# STM32WBA52 register map
File version: 0.1
CPU: CM33 r0p1, little endian, MPU, FPU, 4 interrupt priority bits
Registers are 32-bit, read-write, reset 0x0 unless marked. A register's access mark holds for its fields unless they carry their own. Offsets are from the block's base; [hi:lo] are bit positions; {n}, {i} and the like mark numbered series.

## TIM1 (part 2 of 2) — Advanced-control timers
Base 0x40012C00
Same registers: SEC_TIM1 0x50012C00
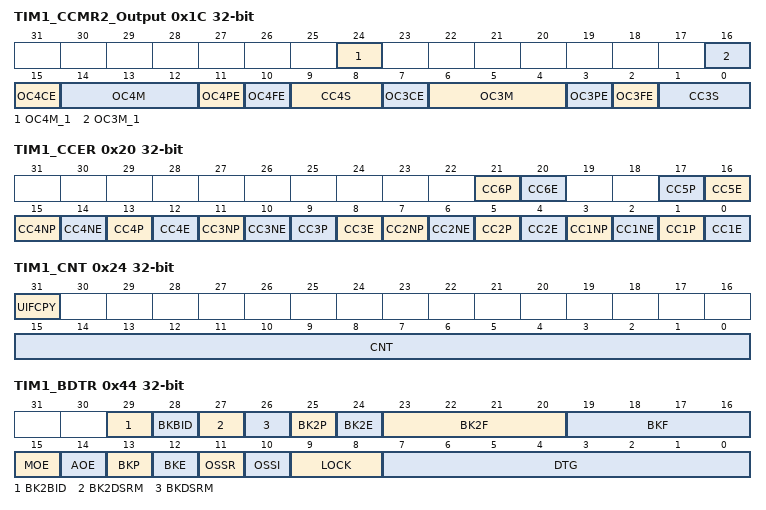
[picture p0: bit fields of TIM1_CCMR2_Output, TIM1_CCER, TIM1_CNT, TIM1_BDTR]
0x1C TIM1_CCMR2_Output (alternate view of TIM1_CCMR2_Input) — TIM1 capture/compare mode register 2 [alternate]
  [24] OC4M_1 — OC4M[3]
  [16] OC3M_1 — OC3M[3]
  [15] OC4CE — Output compare 4 clear enable
  [14:12] OC4M — OC4M[2:0]: Output compare 4 mode Refer to OC3M[3:0] bit description
  [11] OC4PE — Output compare 4 preload enable
  [10] OC4FE — Output compare 4 fast enable
  [9:8] CC4S — Capture/compare 4 selection This bit-field defines the direction of the channel (input/output) as well as the used input. Note: CC4S bits are writable only when the channel is OFF (CC4E = ‘0’ in TIMx_CCER).
    0=CC4 channel is configured as output; 1=CC4 channel is configured as input, tim_ic4 is mapped on tim_ti4; 2=CC4 channel is configured as input, tim_ic4 is mapped on tim_ti3; 3=CC4 channel is configured as input, tim_ic4 is mapped on tim_trc. This mode is working only if an internal trigger input is selected through TS bit (TIMx_SMCR register)
  [7] OC3CE — Output compare 3 clear enable
  [6:4] OC3M — OC3M[2:0]: Output compare 3 mode These bits define the behavior of the output reference signal tim_oc3ref from which tim_oc3 and tim_oc3n are derived. tim_oc3ref is active high whereas tim_oc3 and tim_oc3n active level depends on CC3P and CC3NP bits. Note: These bits can not be modified as long as LOCK level 3 has been programmed (LOCK bits in TIMx_BDTR register) and CC1S=’00’ (the channel is configured in output). Note: In PWM mode, the OCREF level changes only when the result of the comparison changes or when the output compare mode switches from “frozen” mode to “PWM” mode. On channels having a complementary output, this bit field is preloaded. If the CCPC bit is set in the TIMx_CR2 register then the OC3M active bits take the new value from the preloaded bits only when a COM event is generated.
    0=Frozen - The comparison between the output compare register TIMx_CCR3 and the counter TIMx_CNT has no effect on the outputs.(this mode is used to generate a timing base); 1=Set channel 3 to active level on match. tim_oc3ref signal is forced high when the counter TIMx_CNT matches the capture/compare register 3 (TIMx_CCR3).; 2=Set channel 3 to inactive level on match. tim_oc3ref signal is forced low when the counter TIMx_CNT matches the capture/compare register 3 (TIMx_CCR3).; 3=Toggle - tim_oc3ref toggles when TIMx_CNT=TIMx_CCR3; 4=Force inactive level - tim_oc3ref is forced low; 5=Force active level - tim_oc3ref is forced high; 6=PWM mode 1 - In upcounting, channel 3 is active as long as TIMx_CNT<TIMx_CCR3 else inactive. In downcounting, channel 3 is inactive (tim_oc3ref=‘0’) as long as TIMx_CNT>TIMx_CCR3 else active (tim_oc3ref=’1’).; 7=PWM mode 2 - In upcounting, channel 3 is inactive as long as TIMx_CNT<TIMx_CCR3 else active. In downcounting, channel 3 is active as long as TIMx_CNT>TIMx_CCR3 else inactive.; 8=Retrigerrable OPM mode 1 - In up-counting mode, the channel is active until a trigger event is detected (on tim_trgi signal). Then, a comparison is performed as in PWM mode 1 and the channels becomes active again at the next update. In down-counting mode, the channel is inactive until a trigger event is detected (on tim_trgi signal). Then, a comparison is performed as in PWM mode 1 and the channels becomes inactive again at the next update.; 9=Retrigerrable OPM mode 2 - In up-counting mode, the channel is inactive until a trigger event is detected (on tim_trgi signal). Then, a comparison is performed as in PWM mode 2 and the channels becomes inactive again at the next update. In down-counting mode, the channel is active until a trigger event is detected (on tim_trgi signal). Then, a comparison is performed as in PWM mode 1 and the channels becomes active again at the next update.; 10=Pulse on compare: a pulse is generated on tim_oc3ref upon CCR3 match event, as per PWPRSC[2:0] and PW[7:0] bitfields programming in TIMxECR; 11=Direction output. The tim_oc3ref signal is overridden by a copy of the DIR bit.; 12=Combined PWM mode 1 - tim_oc3ref has the same behavior as in PWM mode 1. tim_oc3refc is the logical OR between tim_oc3ref and tim_oc4ref.; 13=Combined PWM mode 2 - tim_oc3ref has the same behavior as in PWM mode 2. tim_oc3refc is the logical AND between tim_oc3ref and tim_oc4ref.; 14=Asymmetric PWM mode 1 - tim_oc3ref has the same behavior as in PWM mode 1. tim_oc3refc outputs tim_oc3ref when the counter is counting up, tim_oc4ref when it is counting down.; 15=Asymmetric PWM mode 2 - tim_oc3ref has the same behavior as in PWM mode 2. tim_oc3refc outputs tim_oc3ref when the counter is counting up, tim_oc4ref when it is counting down.
  [3] OC3PE — Output compare 3 preload enable
  [2] OC3FE — Output compare 3 fast enable
  [1:0] CC3S — Capture/compare 3 selection This bit-field defines the direction of the channel (input/output) as well as the used input. Note: CC3S bits are writable only when the channel is OFF (CC3E = ‘0’ in TIMx_CCER).
    0=CC3 channel is configured as output; 1=CC3 channel is configured as input, tim_ic3 is mapped on tim_ti3; 2=CC3 channel is configured as input, tim_ic3 is mapped on tim_ti4; 3=CC3 channel is configured as input, tim_ic3 is mapped on tim_trc. This mode is working only if an internal trigger input is selected through TS bit (TIMx_SMCR register)
0x20 TIM1_CCER — TIM1 capture/compare enable register
  [4n-3] CC{n}P (n=2..6) — Capture/compare {n} output polarity Refer to CC1P description
  [4n-4] CC{n}E (n=2..6) — Capture/compare {n} output enable Refer to CC1E description
  [15] CC4NP — Capture/compare 4 complementary output polarity Refer to CC1NP description
  [14] CC4NE — Capture/compare 4 complementary output enable Refer to CC1NE description
  [11] CC3NP — Capture/compare 3 complementary output polarity Refer to CC1NP description
  [10] CC3NE — Capture/compare 3 complementary output enable Refer to CC1NE description
  [7] CC2NP — Capture/compare 2 complementary output polarity Refer to CC1NP description
  [6] CC2NE — Capture/compare 2 complementary output enable Refer to CC1NE description
  [3] CC1NP — Capture/compare 1 complementary output polarity CC1 channel configured as output: CC1 channel configured as input: This bit is used in conjunction with CC1P to define the polarity of tim_ti1fp1 and tim_ti2fp1. Refer to CC1P description. Note: This bit is not writable as soon as LOCK level 2 or 3 has been programmed (LOCK bits in TIMx_BDTR register) and CC1S=”00” (channel configured as output). Note: On channels having a complementary output, this bit is preloaded. If the CCPC bit is set in the TIMx_CR2 register then the CC1NP active bit takes the new value from the preloaded bit only when a Commutation event is generated.
    0=tim_oc1n active high; 1=tim_oc1n active low
  [2] CC1NE — Capture/compare 1 complementary output enable Note: On channels having a complementary output, this bit is preloaded. If the CCPC bit is set in the TIMx_CR2 register then the CC1NE active bit takes the new value from the preloaded bit only when a Commutation event is generated.
    0=Off - tim_oc1n is not active. tim_oc1n level is then function of MOE, OSSI, OSSR, OIS1, OIS1N and CC1E bits.; 1=On - tim_oc1n signal is output on the corresponding output pin depending on MOE, OSSI, OSSR, OIS1, OIS1N and CC1E bits
  [1] CC1P — Capture/compare 1 output polarity When CC1 channel is configured as input, both CC1NP/CC1P bits select the active polarity of TI1FP1 and TI2FP1 for trigger or capture operations. CC1NP=0, CC1P=0: non-inverted/rising edge. The circuit is sensitive to TIxFP1 rising edge (capture or trigger operations in reset, external clock or trigger mode), TIxFP1 is not inverted (trigger operation in gated mode or encoder mode). CC1NP=0, CC1P=1: inverted/falling edge. The circuit is sensitive to TIxFP1 falling edge (capture or trigger operations in reset, external clock or trigger mode), TIxFP1 is inverted (trigger operation in gated mode or encoder mode). CC1NP=1, CC1P=1: non-inverted/both edges/ The circuit is sensitive to both TIxFP1 rising and falling edges (capture or trigger operations in reset, external clock or trigger mode), TIxFP1is not inverted (trigger operation in gated mode). This configuration must not be used in encoder mode. CC1NP=1, CC1P=0: the configuration is reserved, it must not be used. Note: This bit is not writable as soon as LOCK level 2 or 3 has been programmed (LOCK bits in TIMx_BDTR register). Note: On channels having a complementary output, this bit is preloaded. If the CCPC bit is set in the TIMx_CR2 register then the CC1P active bit takes the new value from the preloaded bit only when a Commutation event is generated.
    0=OC1 active high (output mode) / Edge sensitivity selection (input mode, see below); 1=OC1 active low (output mode) / Edge sensitivity selection (input mode, see below)
  [0] CC1E — Capture/compare 1 output enable When CC1 channel is configured as output, the OC1 level depends on MOE, OSSI, OSSR, OIS1, OIS1N and CC1NE bits, regardless of the CC1E bits state. Refer to Table�272 for details. Note: On channels having a complementary output, this bit is preloaded. If the CCPC bit is set in the TIMx_CR2 register then the CC1E active bit takes the new value from the preloaded bit only when a Commutation event is generated.
    0=Capture mode disabled / OC1 is not active (see below); 1=Capture mode enabled / OC1 signal is output on the corresponding output pin
0x24 TIM1_CNT access per field — TIM1 counter
  [31] UIFCPY ro — UIF copy This bit is a read-only copy of the UIF bit of the TIMx_ISR register. If the UIFREMAP bit in the TIMxCR1 is reset, bit 31 is reserved and read at 0.
  [15:0] CNT rw — Counter value Non-dithering mode (DITHEN = 0) The register holds the counter value. Dithering mode (DITHEN = 1) The register only holds the non-dithered part in CNT[15:0]. The fractional part is not available.
0x28 TIM1_PSC 16-bit — TIM1 prescaler
  [15:0] PSC — Prescaler value The counter clock frequency (f<sub>tim_cnt_ck</sub>) is equal to f<sub>tim_psc_ck</sub> / (PSC[15:0] + 1). PSC contains the value to be loaded in the active prescaler register at each update event (including when the counter is cleared through UG bit of TIMx_EGR register or through trigger controller when configured in “reset mode”).
0x2C TIM1_ARR reset 0xFFFF — TIM1 auto-reload register
  [19:0] ARR — Auto-reload value ARR is the value to be loaded in the actual auto-reload register. Refer to the Section�28.3.3: Time-base unit on page�1112 for more details about ARR update and behavior. The counter is blocked while the auto-reload value is null. Non-dithering mode (DITHEN = 0) The register holds the auto-reload value. Dithering mode (DITHEN = 1) The register holds the integer part in ARR[19:4]. The ARR[3:0] bitfield contains the dithered part.
0x30 TIM1_RCR 16-bit — TIM1 repetition counter register
  [15:0] REP — Repetition counter reload value This bitfield defines the update rate of the compare registers (i.e. periodic transfers from preload to active registers) when preload registers are enable. It also defines the update interrupt generation rate, if this interrupt is enable. When the repetition down-counter reaches zero, an update event is generated and it restarts counting from REP value. As the repetition counter is reloaded with REP value only at the repetition update event UEV, any write to the TIMx_RCR register is not taken in account until the next repetition update event. It means in PWM mode (REP+1) corresponds to: the number of PWM periods in edge-aligned mode the number of half PWM period in center-aligned mode.
0x34 TIM1_CCR1 — TIM1 capture/compare register 1
  [19:0] CCR1 — Capture/compare 1 value If channel CC1 is configured as output: CCR1 is the value to be loaded in the actual capture/compare 1 register (preload value). It is loaded permanently if the preload feature is not selected in the TIMx_CCMR1 register (bit OC1PE). Else the preload value is copied in the active capture/compare 1 register when an update event occurs. The active capture/compare register contains the value to be compared to the counter TIMx_CNT and signaled on tim_oc1 output. Non-dithering mode (DITHEN = 0) The register holds the compare value in CCR1[15:0]. The CCR1[19:16] bits are reset. Dithering mode (DITHEN = 1) The register holds the integer part in CCR1[19:4]. The CCR1[3:0] bitfield contains the dithered part. If channel CC1 is configured as input: CR1 is the counter value transferred by the last input capture 1 event (tim_ic1). The TIMx_CCR1 register is read-only and cannot be programmed. Non-dithering mode (DITHEN = 0) The register holds the capture value in CCR1[15:0]. The CCR1[19:16] bits are reset. Dithering mode (DITHEN = 1) The register holds the capture in CCR1[19:4]. The CCR1[3:0] bits are reset.
0x38 TIM1_CCR2 — TIM1 capture/compare register 2
  [19:0] CCR2 — Capture/compare 2 value If channel CC2 is configured as output: CCR2 is the value to be loaded in the actual capture/compare 2 register (preload value). It is loaded permanently if the preload feature is not selected in the TIMx_CCMR1 register (bit OC2PE). Else the preload value is copied in the active capture/compare 2 register when an update event occurs. The active capture/compare register contains the value to be compared to the counter TIMx_CNT and signaled on tim_oc2 output. Non-dithering mode (DITHEN = 0) The register holds the compare value in CCR2[15:0]. The CCR2[19:16] bits are reset. Dithering mode (DITHEN = 1) The register holds the integer part in CCR2[19:4]. The CCR2[3:0] bitfield contains the dithered part. If channel CC2 is configured as input: CCR2 is the counter value transferred by the last input capture 2 event (tim_ic2). The TIMx_CCR2 register is read-only and cannot be programmed. Non-dithering mode (DITHEN = 0) The register holds the capture value in CCR2[15:0]. The CCR2[19:16] bits are reset. Dithering mode (DITHEN = 1) The register holds the capture in CCR2[19:4]. The CCR2[3:0] bits are reset.
0x3C TIM1_CCR3 — TIM1 capture/compare register 3
  [19:0] CCR3 — Capture/compare value If channel CC3 is configured as output: CCR3 is the value to be loaded in the actual capture/compare 3 register (preload value). It is loaded permanently if the preload feature is not selected in the TIMx_CCMR2 register (bit OC3PE). Else the preload value is copied in the active capture/compare 3 register when an update event occurs. The active capture/compare register contains the value to be compared to the counter TIMx_CNT and signaled on tim_oc3 output. Non-dithering mode (DITHEN = 0) The register holds the compare value in CCR3[15:0]. The CCR3[19:16] bits are reset. Dithering mode (DITHEN = 1) The register holds the integer part in CCR3[19:4]. The CCR3[3:0] bitfield contains the dithered part. If channel CC3 is configured as input: CCR3 is the counter value transferred by the last input capture 3 event (tim_ic3). The TIMx_CCR3 register is read-only and cannot be programmed. Non-dithering mode (DITHEN = 0) The register holds the capture value in CCR3[15:0]. The CCR3[19:16] bits are reset. Dithering mode (DITHEN = 1) The register holds the capture in CCR3[19:4]. The CCR3[3:0] bits are reset.
0x40 TIM1_CCR4 — TIM1 capture/compare register 4
  [19:0] CCR4 — Capture/compare value If channel CC4 is configured as output: CCR4 is the value to be loaded in the actual capture/compare 4 register (preload value). It is loaded permanently if the preload feature is not selected in the TIMx_CCMR2 register (bit OC4PE). Else the preload value is copied in the active capture/compare 4 register when an update event occurs. The active capture/compare register contains the value to be compared to the counter TIMx_CNT and signalled on tim_oc4 output. Non-dithering mode (DITHEN = 0) The register holds the compare value in CCR4[15:0]. The CCR4[19:16] bits are reset. Dithering mode (DITHEN = 1) The register holds the integer part in CCR4[19:4]. The CCR4[3:0] bitfield contains the dithered part. If channel CC4 is configured as input: CCR4 is the counter value transferred by the last input capture 4 event (tim_ic4). The TIMx_CCR4 register is read-only and cannot be programmed. Non-dithering mode (DITHEN = 0) The register holds the capture value in CCR4[15:0]. The CCR4[19:16] bits are reset. Dithering mode (DITHEN = 1) The register holds the capture in CCR4[19:4]. The CCR4[3:0] bits are reset.
0x44 TIM1_BDTR — TIM1 break and dead-time register
  [29] BK2BID — Break2 bidirectional Refer to BKBID description
  [28] BKBID — Break bidirectional In the bidirectional mode (BKBID bit set to 1), the break input is configured both in input mode and in open drain output mode. Any active break event asserts a low logic level on the Break input to indicate an internal break event to external devices. Note: This bit cannot be modified as long as LOCK level 1 has been programmed (LOCK bits in TIMx_BDTR register). Note: Any write operation to this bit takes a delay of 1 APB clock cycle to become effective.
    0=Break input tim_brk in input mode; 1=Break input tim_brk in bidirectional mode
  [27] BK2DSRM — Break2 disarm Refer to BKDSRM description
  [26] BKDSRM — Break disarm This bit is cleared by hardware when no break source is active. The BKDSRM bit must be set by software to release the bidirectional output control (open-drain output in Hi-Z state) and then be polled it until it is reset by hardware, indicating that the fault condition has disappeared. Note: Any write operation to this bit takes a delay of 1 APB clock cycle to become effective.
    0=Break input tim_brk is armed; 1=Break input tim_brk is disarmed
  [25] BK2P — Break 2 polarity Note: This bit cannot be modified as long as LOCK level 1 has been programmed (LOCK bits in TIMx_BDTR register). Note: Any write operation to this bit takes a delay of 1 APB clock cycle to become effective.
    0=Break input tim_brk2 is active low; 1=Break input tim_brk2 is active high
  [24] BK2E — Break 2 enable This bit enables the complete break 2 protection (including all sources connected to bk_acth and BKIN sources, as per Figure�316: Break and Break2 circuitry overview). Note: The BRKIN2 must only be used with OSSR = OSSI = 1. Note: This bit cannot be modified when LOCK level 1 has been programmed (LOCK bits in TIMx_BDTR register). Note: Any write operation to this bit takes a delay of 1 APB clock cycle to become effective.
    0=Break2 function disabled; 1=Break2 function enabled
  [23:20] BK2F — Break 2 filter This bit-field defines the frequency used to sample tim_brk2 input and the length of the digital filter applied to tim_brk2. The digital filter is made of an event counter in which N consecutive events are needed to validate a transition on the output: Note: This bit cannot be modified when LOCK level 1 has been programmed (LOCK bits in TIMx_BDTR register).
    0=No filter, tim_brk2 acts asynchronously; 1=f<sub>SAMPLING</sub>=f<sub>tim_ker_ck</sub>, N=2; 2=f<sub>SAMPLING</sub>=f<sub>tim_ker_ck</sub>, N=4; 3=f<sub>SAMPLING</sub>=f<sub>tim_ker_ck</sub>, N=8; 4=f<sub>SAMPLING</sub>=f<sub>DTS</sub>/2, N=6; 5=f<sub>SAMPLING</sub>=f<sub>DTS</sub>/2, N=8; 6=f<sub>SAMPLING</sub>=f<sub>DTS</sub>/4, N=6; 7=f<sub>SAMPLING</sub>=f<sub>DTS</sub>/4, N=8; 8=f<sub>SAMPLING</sub>=f<sub>DTS</sub>/8, N=6; 9=f<sub>SAMPLING</sub>=f<sub>DTS</sub>/8, N=8; 10=f<sub>SAMPLING</sub>=f<sub>DTS</sub>/16, N=5; 11=f<sub>SAMPLING</sub>=f<sub>DTS</sub>/16, N=6; 12=f<sub>SAMPLING</sub>=f<sub>DTS</sub>/16, N=8; 13=f<sub>SAMPLING</sub>=f<sub>DTS</sub>/32, N=5; 14=f<sub>SAMPLING</sub>=f<sub>DTS</sub>/32, N=6; 15=f<sub>SAMPLING</sub>=f<sub>DTS</sub>/32, N=8
  [19:16] BKF — Break filter This bit-field defines the frequency used to sample tim_brk input and the length of the digital filter applied to tim_brk. The digital filter is made of an event counter in which N consecutive events are needed to validate a transition on the output: Note: This bit cannot be modified when LOCK level 1 has been programmed (LOCK bits in TIMx_BDTR register).
    0=No filter, tim_brk acts asynchronously; 1=f<sub>SAMPLING</sub>=f<sub>tim_ker_ck</sub>, N=2; 2=f<sub>SAMPLING</sub>=f<sub>tim_ker_ck</sub>, N=4; 3=f<sub>SAMPLING</sub>=f<sub>tim_ker_ck</sub>, N=8; 4=f<sub>SAMPLING</sub>=f<sub>DTS</sub>/2, N=6; 5=f<sub>SAMPLING</sub>=f<sub>DTS</sub>/2, N=8; 6=f<sub>SAMPLING</sub>=f<sub>DTS</sub>/4, N=6; 7=f<sub>SAMPLING</sub>=f<sub>DTS</sub>/4, N=8; 8=f<sub>SAMPLING</sub>=f<sub>DTS</sub>/8, N=6; 9=f<sub>SAMPLING</sub>=f<sub>DTS</sub>/8, N=8; 10=f<sub>SAMPLING</sub>=f<sub>DTS</sub>/16, N=5; 11=f<sub>SAMPLING</sub>=f<sub>DTS</sub>/16, N=6; 12=f<sub>SAMPLING</sub>=f<sub>DTS</sub>/16, N=8; 13=f<sub>SAMPLING</sub>=f<sub>DTS</sub>/32, N=5; 14=f<sub>SAMPLING</sub>=f<sub>DTS</sub>/32, N=6; 15=f<sub>SAMPLING</sub>=f<sub>DTS</sub>/32, N=8
  [15] MOE — Main output enable This bit is cleared asynchronously by hardware as soon as one of the break inputs is active (tim_brk or tim_brk2). It is set by software or automatically depending on the AOE bit. It is acting only on the channels which are configured in output. In response to a break event or if MOE is written to 0: OC and OCN outputs are disabled or forced to idle state depending on the OSSI bit. See OC/OCN enable description for more details (Section�28.6.11: TIM1 capture/compare enable register (TIM1_CCER)).
    0=In response to a break 2 event. OC and OCN outputs are disabled; 1=OC and OCN outputs are enabled if their respective enable bits are set (CCxE, CCxNE in TIMx_CCER register)
  [14] AOE — Automatic output enable Note: This bit can not be modified as long as LOCK level 1 has been programmed (LOCK bits in TIMx_BDTR register).
    0=MOE can be set only by software; 1=MOE can be set by software or automatically at the next update event (if none of the break inputs tim_brk and tim_brk2 is active)
  [13] BKP — Break polarity Note: This bit can not be modified as long as LOCK level 1 has been programmed (LOCK bits in TIMx_BDTR register). Note: Any write operation to this bit takes a delay of 1 APB clock cycle to become effective.
    0=Break input tim_brk is active low; 1=Break input tim_brk is active high
  [12] BKE — Break enable This bit enables the complete break protection (including all sources connected to bk_acth and BKIN sources, as per Figure�316: Break and Break2 circuitry overview). Note: This bit cannot be modified when LOCK level 1 has been programmed (LOCK bits in TIMx_BDTR register). Note: Any write operation to this bit takes a delay of 1 APB clock cycle to become effective.
    0=Break function disabled; 1=Break function enabled
  [11] OSSR — Off-state selection for Run mode This bit is used when MOE=1 on channels having a complementary output which are configured as outputs. OSSR is not implemented if no complementary output is implemented in the timer. See OC/OCN enable description for more details (Section�28.6.11: TIM1 capture/compare enable register (TIM1_CCER)). Note: This bit can not be modified as soon as the LOCK level 2 has been programmed (LOCK bits in TIMx_BDTR register).
    0=When inactive, OC/OCN outputs are disabled (the timer releases the output control which is taken over by the GPIO logic, which forces a Hi-Z state); 1=When inactive, OC/OCN outputs are enabled with their inactive level as soon as CCxE=1 or CCxNE=1 (the output is still controlled by the timer)
  [10] OSSI — Off-state selection for idle mode This bit is used when MOE=0 due to a break event or by a software write, on channels configured as outputs. See OC/OCN enable description for more details (Section�28.6.11: TIM1 capture/compare enable register (TIM1_CCER)). Note: This bit can not be modified as soon as the LOCK level 2 has been programmed (LOCK bits in TIMx_BDTR register).
    0=When inactive, OC/OCN outputs are disabled (the timer releases the output control which is taken over by the GPIO logic and which imposes a Hi-Z state); 1=When inactive, OC/OCN outputs are first forced with their inactive level then forced to their idle level after the deadtime. The timer maintains its control over the output.
  [9:8] LOCK — Lock configuration These bits offer a write protection against software errors. Note: The LOCK bits can be written only once after the reset. Once the TIMx_BDTR register has been written, their content is frozen until the next reset.
    0=LOCK OFF - No bit is write protected; 1=LOCK Level 1 = DTG bits in TIMx_BDTR register, OISx and OISxN bits in TIMx_CR2 register and BKBID/BK2BID/BKE/BKP/AOE bits in TIMx_BDTR register can no longer be written; 2=LOCK Level 2 = LOCK Level 1 + CC Polarity bits (CCxP/CCxNP bits in TIMx_CCER register, as long as the related channel is configured in output through the CCxS bits) as well as OSSR and OSSI bits can no longer be written; 3=LOCK Level 3 = LOCK Level 2 + CC Control bits (OCxM and OCxPE bits in TIMx_CCMRx registers, as long as the related channel is configured in output through the CCxS bits) can no longer be written
  [7:0] DTG — Dead-time generator setup This bit-field defines the duration of the dead-time inserted between the complementary outputs. DT correspond to this duration. DTG[7:5]=0xx => DT=DTG[7:0]x t<sub>dtg</sub> with t<sub>dtg</sub>=t<sub>DTS</sub>. DTG[7:5]=10x => DT=(64+DTG[5:0])xt<sub>dtg</sub> with T<sub>dtg</sub>=2xt<sub>DTS</sub>. DTG[7:5]=110 => DT=(32+DTG[4:0])xt<sub>dtg</sub> with T<sub>dtg</sub>=8xt<sub>DTS</sub>. DTG[7:5]=111 => DT=(32+DTG[4:0])xt<sub>dtg</sub> with T<sub>dtg</sub>=16xt<sub>DTS</sub>. Example if T<sub>DTS</sub>=125ns (8MHz), dead-time possible values are: 0 to 15875 ns by 125 ns steps, 16 us to 31750 ns by 250 ns steps, 32 us to 63us by 1 us steps, 64 us to 126 us by 2 us steps Note: This bit-field can not be modified as long as LOCK level 1, 2 or 3 has been programmed (LOCK bits in TIMx_BDTR register).
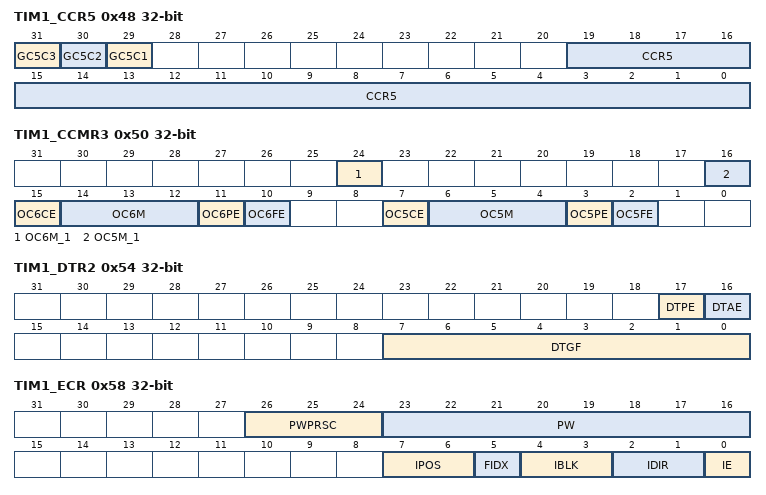
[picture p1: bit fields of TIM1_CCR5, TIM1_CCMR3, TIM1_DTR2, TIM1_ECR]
0x48 TIM1_CCR5 — TIM1 capture/compare register 5
  [31] GC5C3 — Group channel 5 and channel 3 Distortion on channel 3 output: This bit can either have immediate effect or be preloaded and taken into account after an update event (if preload feature is selected in TIMxCCMR2). Note: it is also possible to apply this distortion on combined PWM signals.
    0=No effect of tim_oc5ref on tim_oc3refc; 1=tim_oc3refc is the logical AND of tim_oc3ref and tim_oc5ref
  [30] GC5C2 — Group channel 5 and channel 2 Distortion on channel 2 output: This bit can either have immediate effect or be preloaded and taken into account after an update event (if preload feature is selected in TIMxCCMR1). Note: it is also possible to apply this distortion on combined PWM signals.
    0=No effect of tim_oc5ref on tim_oc2refc; 1=tim_oc2refc is the logical AND of tim_oc2ref and tim_oc5ref
  [29] GC5C1 — Group channel 5 and channel 1 Distortion on channel 1 output: This bit can either have immediate effect or be preloaded and taken into account after an update event (if preload feature is selected in TIMxCCMR1). Note: it is also possible to apply this distortion on combined PWM signals.
    0=No effect of oc5ref on oc1refc; 1=oc1refc is the logical AND of oc1ref and oc5ref
  [19:0] CCR5 — Capture/compare 5 value CCR5 is the value to be loaded in the actual capture/compare 5 register (preload value). It is loaded permanently if the preload feature is not selected in the TIMx_CCMR3 register (bit OC5PE). Else the preload value is copied in the active capture/compare 5 register when an update event occurs. The active capture/compare register contains the value to be compared to the counter TIMx_CNT and signaled on tim_oc5 output. Non-dithering mode (DITHEN = 0) The register holds the compare value in CCR5[15:0]. The CCR5[19:16] bits are reset. Dithering mode (DITHEN = 1) The register holds the integer part in CCR5[19:4]. The CCR5[3:0] bitfield contains the dithered part.
0x4C TIM1_CCR6 — TIM1 capture/compare register 6
  [19:0] CCR6 — Capture/compare 6 value CCR6 is the value to be loaded in the actual capture/compare 6 register (preload value). It is loaded permanently if the preload feature is not selected in the TIMx_CCMR3 register (bit OC6PE). Else the preload value is copied in the active capture/compare 6 register when an update event occurs. The active capture/compare register contains the value to be compared to the counter TIMx_CNT and signaled on tim_oc6 output. Non-dithering mode (DITHEN = 0) The register holds the compare value in CCR6[15:0]. The CCR6[19:16] bits are reset. Dithering mode (DITHEN = 1) The register holds the integer part in CCR6[19:4]. The CCR6[3:0] bitfield contains the dithered part.
0x50 TIM1_CCMR3 — TIM1 capture/compare mode register 3
  [24] OC6M_1 — OC6M[3]
  [16] OC5M_1 — OC5M[3]
  [15] OC6CE — Output compare 6 clear enable
  [14:12] OC6M — OC6M[2:0]: Output compare 6 mode
  [11] OC6PE — Output compare 6 preload enable
  [10] OC6FE — Output compare 6 fast enable
  [7] OC5CE — Output compare 5 clear enable
  [6:4] OC5M — OC5M[2:0]: Output compare 5 mode
  [3] OC5PE — Output compare 5 preload enable
  [2] OC5FE — Output compare 5 fast enable
0x54 TIM1_DTR2 — TIM1 timer deadtime register 2
  [17] DTPE — Deadtime preload enable Note: This bit can not be modified as long as LOCK level 1, 2 or 3 has been programmed (LOCK bits in TIMx_BDTR register).
    0=Deadtime value is not preloaded; 1=Deadtime value preload is enabled
  [16] DTAE — Deadtime asymmetric enable Note: This bit can not be modified as long as LOCK level 1, 2 or 3 has been programmed (LOCK bits in TIMx_BDTR register).
    0=Deadtime on rising and falling edges are identical, and defined with DTG[7:0] register; 1=Deadtime on rising edge is defined with DTG[7:0] register and deadtime on falling edge is defined with DTGF[7:0] bits
  [7:0] DTGF — Dead-time falling edge generator setup This bit-field defines the duration of the dead-time inserted between the complementary outputs, on the falling edge. DTGF[7:5]=0xx => DTF=DTGF[7:0]x t<sub>dtg</sub> with t<sub>dtg</sub>=t<sub>DTS</sub>. DTGF[7:5]=10x => DTF=(64+DTGF[5:0])xt<sub>dtg</sub> with T<sub>dtg</sub>=2xt<sub>DTS</sub>. DTGF[7:5]=110 => DTF=(32+DTGF[4:0])xt<sub>dtg</sub> with T<sub>dtg</sub>=8xt<sub>DTS</sub>. DTGF[7:5]=111 => DTF=(32+DTGF[4:0])xt<sub>dtg</sub> with T<sub>dtg</sub>=16xt<sub>DTS</sub>. Example if T<sub>DTS</sub>=125ns (8MHz), dead-time possible values are: 0 to 15875 ns by 125 ns steps, 16 us to 31750 ns by 250 ns steps, 32 us to 63us by 1 us steps, 64 us to 126 us by 2 us steps Note: This bit-field can not be modified as long as LOCK level 1, 2 or 3 has been programmed (LOCK bits in TIMx_BDTR register).
0x58 TIM1_ECR — TIM1 timer encoder control register
  [26:24] PWPRSC — Pulse width prescaler This bitfield sets the clock prescaler for the pulse generator, as following: t<sub>PWG</sub> = (2<sup>(PWPRSC[2:0])</sup>) x t<sub>tim_ker_ck</sub>
  [23:16] PW — Pulse width This bitfield defines the pulse duration, as following: t<sub>PW</sub> = PW[7:0] x t<sub>PWG</sub>
  [7:6] IPOS — Index positioning In quadrature encoder mode (SMS[3:0] = 0001, 0010, 0011, 1110, 1111), this bit indicates in which AB input configuration the Index event resets the counter. In directional clock mode or clock plus direction mode (SMS[3:0] = 1010, 1011, 1100, 1101), these bits indicates on which level the Index event resets the counter. In bidirectional clock mode, this applies for both clock inputs. x0: Index resets the counter when clock is 0 x1: Index resets the counter when clock is 1 Note: IPOS[1] bit is not significant
    0=Index resets the counter when AB = 00; 1=Index resets the counter when AB = 01; 2=Index resets the counter when AB = 10; 3=Index resets the counter when AB = 11
  [5] FIDX — First index This bit indicates if the first index only is taken into account
    0=Index is always active; 1=the first Index only resets the counter
  [4:3] IBLK — Index blanking This bit indicates if the Index event is conditioned by the tim_ti3 or tim_ti4 input
    0=Index always active; 1=Index disabled when tim_ti3 input is active, as per CC3P bitfield; 2=Index disabled when tim_ti4 input is active, as per CC4P bitfield
  [2:1] IDIR — Index direction This bit indicates in which direction the Index event resets the counter. Note: The IDR[1:0] bitfield must be written when IE bit is reset (index disabled).
    0=Index resets the counter whatever the direction; 1=Index resets the counter when up-counting only; 2=Index resets the counter when down-counting only
  [0] IE — Index enable This bit indicates if the Index event resets the counter.
    0=Index disabled; 1=Index enabled
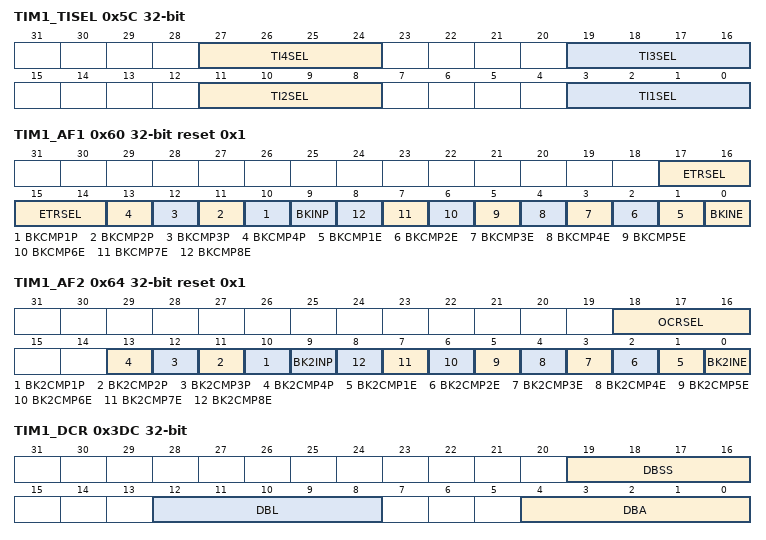
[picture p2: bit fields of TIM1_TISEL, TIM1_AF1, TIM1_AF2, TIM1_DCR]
0x5C TIM1_TISEL — TIM1 timer input selection register
  [27:24] TI4SEL — Selects tim_ti4[15:0] input ... Refer to Section�28.3.2: TIM1 pins and internal signals for interconnects list.
    0=tim_ti4_in0: TIMx_CH4; 1=tim_ti4_in1; 15=tim_ti4_in15
  [19:16] TI3SEL — Selects tim_ti3[15:0] input ... Refer to Section�28.3.2: TIM1 pins and internal signals for interconnects list.
    0=tim_ti3_in0: TIMx_CH2; 1=tim_ti3_in1; 15=tim_ti3_in15
  [11:8] TI2SEL — Selects tim_ti2[15:0] input ... Refer to Section�28.3.2: TIM1 pins and internal signals for interconnects list.
    0=tim_ti2_in0: TIMx_CH2; 1=tim_ti2_in1; 15=tim_ti2_in15
  [3:0] TI1SEL — Selects tim_ti1[15:0] input ... Refer to Section�28.3.2: TIM1 pins and internal signals for interconnects list.
    0=tim_ti1_in0: TIMx_CH1; 1=tim_ti1_in1; 15=tim_ti1_in15
0x60 TIM1_AF1 reset 0x1 — TIM1 alternate function option register 1
  [17:14] ETRSEL — etr_in source selection These bits select the etr_in input source. ... Refer to Section�28.3.2: TIM1 pins and internal signals for product specific implementation. Note: These bits can not be modified as long as LOCK level 1 has been programmed (LOCK bits in TIMx_BDTR register).
    0=tim_etr0: TIMx_ETR input; 1=tim_etr1; 15=tim_etr15
  [n+9] BKCMP{n}P (n=1..4) — tim_brk_cmp{n} input polarity This bit selects the tim_brk_cmp{n} input sensitivity. It must be programmed together with the BKP polarity bit. Note: This bit can not be modified as long as LOCK level 1 has been programmed (LOCK bits in TIMx_BDTR register).
    0=tim_brk_cmp{n} input polarity is not inverted (active low if BKP�=�0, active high if BKP�=�1); 1=tim_brk_cmp{n} input polarity is inverted (active high if BKP�=�0, active low if BKP�=�1)
  [9] BKINP — TIMx_BKIN input polarity This bit selects the TIMx_BKIN alternate function input sensitivity. It must be programmed together with the BKP polarity bit. Note: This bit can not be modified as long as LOCK level 1 has been programmed (LOCK bits in TIMx_BDTR register).
    0=TIMx_BKIN input polarity is not inverted (active low if BKP�=�0, active high if BKP�=�1); 1=TIMx_BKIN input polarity is inverted (active high if BKP�=�0, active low if BKP�=�1)
  [n] BKCMP{n}E (n=1..8) — tim_brk_cmp{n} enable This bit enables the tim_brk_cmp{n} for the timer’s tim_brk input. tim_brk_cmp{n} output is ‘ORed’ with the other tim_brk sources. Note: This bit can not be modified as long as LOCK level 1 has been programmed (LOCK bits in TIMx_BDTR register).
    0=tim_brk_cmp{n} input disabled; 1=tim_brk_cmp{n} input enabled
  [0] BKINE — TIMx_BKIN input enable This bit enables the TIMx_BKIN alternate function input for the timer’s tim_brk input. TIMx_BKIN input is ‘ORed’ with the other tim_brk sources. Note: This bit can not be modified as long as LOCK level 1 has been programmed (LOCK bits in TIMx_BDTR register).
    0=TIMx_BKIN input disabled; 1=TIMx_BKIN input enabled
0x64 TIM1_AF2 reset 0x1 — TIM1 alternate function register 2
  [18:16] OCRSEL — ocref_clr source selection These bits select the ocref_clr input source. ... Refer to Section�28.3.2: TIM1 pins and internal signals for product specific information. Note: These bits can not be modified as long as LOCK level 1 has been programmed (LOCK bits in TIMx_BDTR register).
    0=tim_ocref_clr0; 1=tim_ocref_clr1; 7=tim_ocref_clr7
  [n+9] BK2CMP{n}P (n=1..4) — tim_brk2_cmp{n} input polarity This bit selects the tim_brk2_cmp{n} input sensitivity. It must be programmed together with the BK2P polarity bit. Note: This bit can not be modified as long as LOCK level 1 has been programmed (LOCK bits in TIMx_BDTR register).
    0=tim_brk2_cmp{n} input polarity is not inverted (active low if BK2P�=�0, active high if BK2P�=�1); 1=tim_brk2_cmp{n} input polarity is inverted (active high if BK2P�=�0, active low if BK2P�=�1)
  [9] BK2INP — TIMx_BKIN2 input polarity This bit selects the TIMx_BKIN2 alternate function input sensitivity. It must be programmed together with the BK2P polarity bit. Note: This bit can not be modified as long as LOCK level 1 has been programmed (LOCK bits in TIMx_BDTR register).
    0=TIMx_BKIN2 input polarity is not inverted (active low if BK2P�=�0, active high if BK2P�=�1); 1=TIMx_BKIN2 input polarity is inverted (active high if BK2P�=�0, active low if BK2P�=�1)
  [n] BK2CMP{n}E (n=1..8) — tim_brk2_cmp{n} enable This bit enables the tim_brk2_cmp{n} for the timer’s tim_brk2 input. tim_brk2_cmp{n} output is ‘ORed’ with the other tim_brk2 sources. Note: This bit can not be modified as long as LOCK level 1 has been programmed (LOCK bits in TIMx_BDTR register).
    0=tim_brk2_cmp{n} input disabled; 1=tim_brk2_cmp{n} input enabled
  [0] BK2INE — TIMx_BKIN2 input enable This bit enables the TIMx_BKIN2 alternate function input for the timer’s tim_brk2 input. TIMx_BKIN2 input is ‘ORed’ with the other tim_brk2 sources. Note: This bit can not be modified as long as LOCK level 1 has been programmed (LOCK bits in TIMx_BDTR register).
    0=TIMx_BKIN2 input disabled; 1=TIMx_BKIN2 input enabled
0x3DC TIM1_DCR — TIM1 DMA control register
  [19:16] DBSS — DMA burst source selection This bitfield defines the interrupt source that triggers the DMA burst transfers (the timer recognizes a burst transfer when a read or a write access is done to the TIMx_DMAR address). Others: reserved
    1=Update; {v}=CC{v-1} (v=2..5); 6=COM; 7=Trigger
  [12:8] DBL — DMA burst length This 5-bit vector defines the length of DMA transfers (the timer recognizes a burst transfer when a read or a write access is done to the TIMx_DMAR address), i.e. the number of transfers. Transfers can be in half-words or in bytes (see example below). ... Example: Let us consider the following transfer: DBL = 7 bytes & DBA = TIM2_CR1. If DBL = 7 bytes and DBA = TIM2_CR1 represents the address of the byte to be transferred, the address of the transfer should be given by the following equation: (TIMx_CR1 address) + DBA + (DMA index), where DMA index = DBL In this example, 7 bytes are added to (TIMx_CR1 address) + DBA, which gives us the address from/to which the data are copied. In this case, the transfer is done to 7 registers starting from the following address: (TIMx_CR1 address) + DBA According to the configuration of the DMA Data Size, several cases may occur: If the DMA Data Size is configured in half-words, 16-bit data are transferred to each of the 7 registers. If the DMA Data Size is configured in bytes, the data are also transferred to 7 registers: the first register contains the first MSB byte, the second register, the first LSB byte and so on. So with the transfer Timer, one also has to specify the size of data transferred by DMA.
    0=1 transfer; 1=2 transfers; 2=3 transfers; 26=26 transfers
  [4:0] DBA — DMA base address This 5-bits vector defines the base-address for DMA transfers (when read/write access are done through the TIMx_DMAR address). DBA is defined as an offset starting from the address of the TIMx_CR1 register. Example: ...
    0=TIMx_CR1; 1=TIMx_CR2; 2=TIMx_SMCR
0x3E0 TIM1_DMAR — TIM1 DMA address for full transfer
  [31:0] DMAB — DMA register for burst accesses A read or write operation to the DMAR register accesses the register located at the address (TIMx_CR1 address) + (DBA + DMA index) x 4 where TIMx_CR1 address is the address of the control register 1, DBA is the DMA base address configured in TIMx_DCR register, DMA index is automatically controlled by the DMA transfer, and ranges from 0 to DBL (DBL configured in TIMx_DCR).
